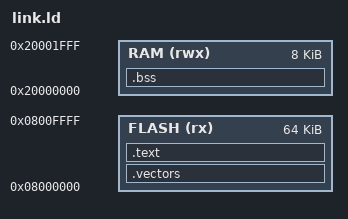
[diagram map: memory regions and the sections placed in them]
ENTRY(Reset_Handler)
MEMORY {
    FLASH (rx) : ORIGIN = 0x08000000, LENGTH = 64K
    RAM (rwx) : ORIGIN = 0x20000000, LENGTH = 8K
}
SECTIONS {
    .vectors : { KEEP(*(.vectors)) } > FLASH
    .text : { *(.text*) *(.rodata*) } > FLASH
    .bss (NOLOAD) : {
        . = ALIGN(4);
        _bss_start = .;
        *(.bss*) *(COMMON)
        . = ALIGN(4);
        _bss_end = .;
    } > RAM
    /DISCARD/ : { *(.comment*) *(.note*) *(.ARM.exidx*) *(.ARM.extab*) }
}
